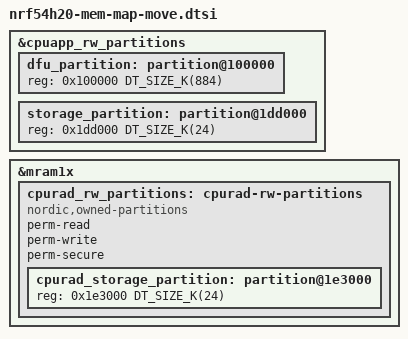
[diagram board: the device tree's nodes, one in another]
/*
 * Copyright (c) 2024 Nordic Semiconductor
 * SPDX-License-Identifier: LicenseRef-Nordic-5-Clause
 */
/delete-node/ &dfu_partition;
/delete-node/ &storage_partition;

&cpuapp_rw_partitions {
	dfu_partition: partition@100000 {
		reg = < 0x100000 DT_SIZE_K(884) >;
	};

	storage_partition: partition@1dd000 {
		reg = < 0x1dd000 DT_SIZE_K(24) >;
	};
};

&mram1x {
	cpurad_rw_partitions: cpurad-rw-partitions {
		compatible = "nordic,owned-partitions", "fixed-partitions";
		perm-read;
		perm-write;
		perm-secure;
		#address-cells = <1>;
		#size-cells = <1>;

		cpurad_storage_partition: partition@1e3000 {
			reg = <0x1e3000 DT_SIZE_K(24)>;
		};
	};
};
